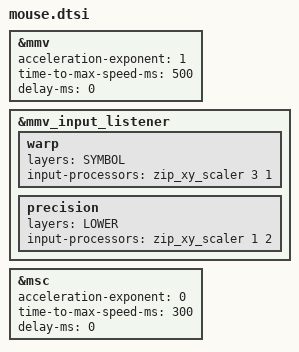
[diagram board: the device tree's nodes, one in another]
#define ZMK_POINTING_DEFAULT_MOVE_VAL 600
#define ZMK_POINTING_DEFAULT_SCRL_VAL 20

#include <dt-bindings/zmk/pointing.h>
#include <input/processors.dtsi>

&mmv {
  acceleration-exponent = <1>;      // 1
  time-to-max-speed-ms = <500>;    // 300
  delay-ms = <0>;                   // 0
};

&mmv_input_listener {
  warp {
    layers = <SYMBOL>;
    input-processors = <&zip_xy_scaler 3 1>;
  };
  precision {
    layers = <LOWER>;
    input-processors = <&zip_xy_scaler 1 2>;
  };
};

&msc {
  acceleration-exponent = <0>;      // 1
  time-to-max-speed-ms = <300>;    // 300
  delay-ms = <0>;                   // 0
};
